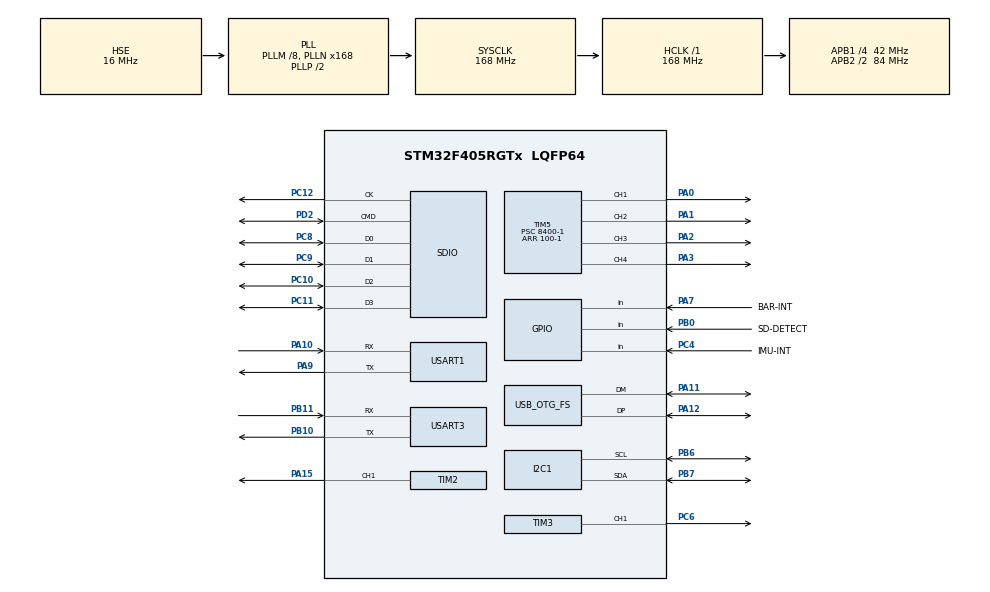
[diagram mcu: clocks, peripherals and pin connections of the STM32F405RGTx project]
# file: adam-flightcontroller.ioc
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Mcu.Family=STM32F4
Mcu.Name=STM32F405RGTx
Mcu.Package=LQFP64
NVIC.OTG_FS_IRQn=true\:0\:0\:false\:false\:true\:false\:true\:true
NVIC.PriorityGroup=NVIC_PRIORITYGROUP_4
PA0-WKUP.Signal=S_TIM5_CH1
PA1.Signal=S_TIM5_CH2
PA10.Mode=Asynchronous
PA10.Signal=USART1_RX
PA11.Mode=Device_Only
PA11.Signal=USB_OTG_FS_DM
PA12.Mode=Device_Only
PA12.Signal=USB_OTG_FS_DP
PA13.Mode=Trace_Asynchronous_SW
PA13.Signal=SYS_JTMS-SWDIO
PA14.Mode=Trace_Asynchronous_SW
PA14.Signal=SYS_JTCK-SWCLK
PA15.Signal=S_TIM2_CH1_ETR
PA2.Signal=S_TIM5_CH3
PA3.Signal=S_TIM5_CH4
PA7.GPIO_Label=BAR-INT
PA7.Signal=GPIO_Input
PA9.Mode=Asynchronous
PA9.Signal=USART1_TX
PB0.GPIO_Label=SD-DETECT
PB0.Signal=GPIO_Input
PB10.Mode=Asynchronous
PB10.Signal=USART3_TX
PB11.Mode=Asynchronous
PB11.Signal=USART3_RX
PB3.Mode=Trace_Asynchronous_SW
PB3.Signal=SYS_JTDO-SWO
PB6.Mode=I2C
PB6.Signal=I2C1_SCL
PB7.Mode=I2C
PB7.Signal=I2C1_SDA
PC10.Mode=SD_4_bits_Wide_bus
PC10.Signal=SDIO_D2
PC11.Mode=SD_4_bits_Wide_bus
PC11.Signal=SDIO_D3
PC12.Mode=SD_4_bits_Wide_bus
PC12.Signal=SDIO_CK
PC14-OSC32_IN.Mode=LSE-External-Oscillator
PC14-OSC32_IN.Signal=RCC_OSC32_IN
PC15-OSC32_OUT.Mode=LSE-External-Oscillator
PC15-OSC32_OUT.Signal=RCC_OSC32_OUT
PC4.GPIO_Label=IMU-INT
PC4.Signal=GPIO_Input
PC6.Signal=S_TIM3_CH1
PC8.Mode=SD_4_bits_Wide_bus
PC8.Signal=SDIO_D0
PC9.Mode=SD_4_bits_Wide_bus
PC9.Signal=SDIO_D1
PD2.Mode=SD_4_bits_Wide_bus
PD2.Signal=SDIO_CMD
PH0-OSC_IN.Mode=HSE-External-Oscillator
PH0-OSC_IN.Signal=RCC_OSC_IN
PH1-OSC_OUT.Mode=HSE-External-Oscillator
PH1-OSC_OUT.Signal=RCC_OSC_OUT
ProjectManager.HeapSize=0x200
ProjectManager.StackSize=0x400
ProjectManager.TargetToolchain=Makefile
RCC.48MHZClocksFreq_Value=48000000
RCC.AHBFreq_Value=168000000
RCC.APB1CLKDivider=RCC_HCLK_DIV4
RCC.APB1Freq_Value=42000000
RCC.APB1TimFreq_Value=84000000
RCC.APB2CLKDivider=RCC_HCLK_DIV2
RCC.APB2Freq_Value=84000000
RCC.APB2TimFreq_Value=168000000
RCC.CortexFreq_Value=168000000
RCC.HCLKFreq_Value=168000000
RCC.HSE_VALUE=16000000
RCC.HSI_VALUE=16000000
RCC.PLLM=8
RCC.PLLN=168
RCC.PLLQ=7
RCC.SYSCLKFreq_VALUE=168000000
RCC.SYSCLKSource=RCC_SYSCLKSOURCE_PLLCLK
RCC.VCOOutputFreq_Value=336000000
SH.S_TIM2_CH1_ETR.0=TIM2_CH1,PWM Generation1 CH1
SH.S_TIM3_CH1.0=TIM3_CH1,PWM Generation1 CH1
SH.S_TIM5_CH1.0=TIM5_CH1,PWM Generation1 CH1
SH.S_TIM5_CH2.0=TIM5_CH2,PWM Generation2 CH2
SH.S_TIM5_CH3.0=TIM5_CH3,PWM Generation3 CH3
SH.S_TIM5_CH4.0=TIM5_CH4,Output Compare4 CH4
TIM2.Channel-PWM\ Generation1\ CH1=TIM_CHANNEL_1
TIM2.Period=100-1
TIM2.Prescaler=8400-1
TIM3.Channel-PWM\ Generation1\ CH1=TIM_CHANNEL_1
TIM3.Period=100-1
TIM3.Prescaler=8400-1
TIM5.Channel-Output\ Compare4\ CH4=TIM_CHANNEL_4
TIM5.Channel-PWM\ Generation1\ CH1=TIM_CHANNEL_1
TIM5.Channel-PWM\ Generation2\ CH2=TIM_CHANNEL_2
TIM5.Channel-PWM\ Generation3\ CH3=TIM_CHANNEL_3
TIM5.Period=100-1
TIM5.Prescaler=8400-1
USART1.VirtualMode=VM_ASYNC
USART3.VirtualMode=VM_ASYNC
USB_DEVICE.CLASS_NAME_FS=CDC
USB_DEVICE.VirtualMode-CDC_FS=Cdc
USB_DEVICE.VirtualModeFS=Cdc_FS
USB_OTG_FS.VirtualMode=Device_Only
VP_TIM2_VS_ClockSourceINT.Mode=Internal
VP_TIM3_VS_ClockSourceINT.Mode=Internal
VP_TIM5_VS_ClockSourceINT.Mode=Internal
VP_USB_DEVICE_VS_USB_DEVICE_CDC_FS.Mode=CDC_FS
board=custom

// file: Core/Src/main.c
/* USER CODE BEGIN Header */
/**
  ******************************************************************************
  * @file           : main.c
  * @brief          : Main program body
  ******************************************************************************
  * @attention
  *
  * Copyright (c) 2023 STMicroelectronics.
  * All rights reserved.
  *
  * This software is licensed under terms that can be found in the LICENSE file
  * in the root directory of this software component.
  * If no LICENSE file comes with this software, it is provided AS-IS.
  *
  ******************************************************************************
  */
/* USER CODE END Header */
#include "main.h"
#include "usb_device.h"

I2C_HandleTypeDef hi2c1;

SD_HandleTypeDef hsd;

TIM_HandleTypeDef htim2;
TIM_HandleTypeDef htim3;
TIM_HandleTypeDef htim5;

UART_HandleTypeDef huart1;
UART_HandleTypeDef huart3;

void SystemClock_Config(void);
static void MX_GPIO_Init(void);
static void MX_I2C1_Init(void);
static void MX_SDIO_SD_Init(void);
static void MX_TIM2_Init(void);
static void MX_TIM3_Init(void);
static void MX_TIM5_Init(void);
static void MX_USART1_UART_Init(void);
static void MX_USART3_UART_Init(void);

int main(void)
{

  /* MCU Configuration--------------------------------------------------------*/

  /* Reset of all peripherals, Initializes the Flash interface and the Systick. */
  HAL_Init();

  /* Configure the system clock */
  SystemClock_Config();

  /* Initialize all configured peripherals */
  MX_GPIO_Init();
  MX_I2C1_Init();
  MX_SDIO_SD_Init();
  MX_TIM2_Init();
  MX_TIM3_Init();
  MX_TIM5_Init();
  MX_USART1_UART_Init();
  MX_USART3_UART_Init();
  MX_USB_DEVICE_Init();
  /* USER CODE BEGIN 2 */
  HAL_TIM_PWM_Start(&htim3, TIM_CHANNEL_1);
  uint8_t intensity = 0;

  /* USER CODE END 2 */

  /* Infinite loop */
  while (1)
  {
    htim3.Instance->CCR1 = 100 - intensity;

    intensity += 5;
    if (intensity > 100) {
      intensity = 0;
    }

    HAL_Delay(100);
  }
}

void SystemClock_Config(void)
{
  RCC_OscInitTypeDef RCC_OscInitStruct = {0};
  RCC_ClkInitTypeDef RCC_ClkInitStruct = {0};

  /** Configure the main internal regulator output voltage
  */
  __HAL_RCC_PWR_CLK_ENABLE();
  __HAL_PWR_VOLTAGESCALING_CONFIG(PWR_REGULATOR_VOLTAGE_SCALE1);

  /** Initializes the RCC Oscillators according to the specified parameters
  * in the RCC_OscInitTypeDef structure.
  */
  RCC_OscInitStruct.OscillatorType = RCC_OSCILLATORTYPE_HSE;
  RCC_OscInitStruct.HSEState = RCC_HSE_ON;
  RCC_OscInitStruct.PLL.PLLState = RCC_PLL_ON;
  RCC_OscInitStruct.PLL.PLLSource = RCC_PLLSOURCE_HSE;
  RCC_OscInitStruct.PLL.PLLM = 8;
  RCC_OscInitStruct.PLL.PLLN = 168;
  RCC_OscInitStruct.PLL.PLLP = RCC_PLLP_DIV2;
  RCC_OscInitStruct.PLL.PLLQ = 7;
  if (HAL_RCC_OscConfig(&RCC_OscInitStruct) != HAL_OK)
  {
    Error_Handler();
  }

  /** Initializes the CPU, AHB and APB buses clocks
  */
  RCC_ClkInitStruct.ClockType = RCC_CLOCKTYPE_HCLK|RCC_CLOCKTYPE_SYSCLK
                              |RCC_CLOCKTYPE_PCLK1|RCC_CLOCKTYPE_PCLK2;
  RCC_ClkInitStruct.SYSCLKSource = RCC_SYSCLKSOURCE_PLLCLK;
  RCC_ClkInitStruct.AHBCLKDivider = RCC_SYSCLK_DIV1;
  RCC_ClkInitStruct.APB1CLKDivider = RCC_HCLK_DIV4;
  RCC_ClkInitStruct.APB2CLKDivider = RCC_HCLK_DIV2;

  if (HAL_RCC_ClockConfig(&RCC_ClkInitStruct, FLASH_LATENCY_5) != HAL_OK)
  {
    Error_Handler();
  }
}

static void MX_I2C1_Init(void)
{

  hi2c1.Instance = I2C1;
  hi2c1.Init.ClockSpeed = 100000;
  hi2c1.Init.DutyCycle = I2C_DUTYCYCLE_2;
  hi2c1.Init.OwnAddress1 = 0;
  hi2c1.Init.AddressingMode = I2C_ADDRESSINGMODE_7BIT;
  hi2c1.Init.DualAddressMode = I2C_DUALADDRESS_DISABLE;
  hi2c1.Init.OwnAddress2 = 0;
  hi2c1.Init.GeneralCallMode = I2C_GENERALCALL_DISABLE;
  hi2c1.Init.NoStretchMode = I2C_NOSTRETCH_DISABLE;
  if (HAL_I2C_Init(&hi2c1) != HAL_OK)
  {
    Error_Handler();
  }

}

static void MX_SDIO_SD_Init(void)
{

  hsd.Instance = SDIO;
  hsd.Init.ClockEdge = SDIO_CLOCK_EDGE_RISING;
  hsd.Init.ClockBypass = SDIO_CLOCK_BYPASS_DISABLE;
  hsd.Init.ClockPowerSave = SDIO_CLOCK_POWER_SAVE_DISABLE;
  hsd.Init.BusWide = SDIO_BUS_WIDE_4B;
  hsd.Init.HardwareFlowControl = SDIO_HARDWARE_FLOW_CONTROL_DISABLE;
  hsd.Init.ClockDiv = 0;
  if (HAL_SD_Init(&hsd) != HAL_OK)
  {
    Error_Handler();
  }
  if (HAL_SD_ConfigWideBusOperation(&hsd, SDIO_BUS_WIDE_4B) != HAL_OK)
  {
    Error_Handler();
  }

}

static void MX_TIM2_Init(void)
{

  TIM_ClockConfigTypeDef sClockSourceConfig = {0};
  TIM_MasterConfigTypeDef sMasterConfig = {0};
  TIM_OC_InitTypeDef sConfigOC = {0};

  htim2.Instance = TIM2;
  htim2.Init.Prescaler = 8400-1;
  htim2.Init.CounterMode = TIM_COUNTERMODE_UP;
  htim2.Init.Period = 100-1;
  htim2.Init.ClockDivision = TIM_CLOCKDIVISION_DIV1;
  htim2.Init.AutoReloadPreload = TIM_AUTORELOAD_PRELOAD_DISABLE;
  if (HAL_TIM_Base_Init(&htim2) != HAL_OK)
  {
    Error_Handler();
  }
  sClockSourceConfig.ClockSource = TIM_CLOCKSOURCE_INTERNAL;
  if (HAL_TIM_ConfigClockSource(&htim2, &sClockSourceConfig) != HAL_OK)
  {
    Error_Handler();
  }
  if (HAL_TIM_PWM_Init(&htim2) != HAL_OK)
  {
    Error_Handler();
  }
  sMasterConfig.MasterOutputTrigger = TIM_TRGO_RESET;
  sMasterConfig.MasterSlaveMode = TIM_MASTERSLAVEMODE_DISABLE;
  if (HAL_TIMEx_MasterConfigSynchronization(&htim2, &sMasterConfig) != HAL_OK)
  {
    Error_Handler();
  }
  sConfigOC.OCMode = TIM_OCMODE_PWM1;
  sConfigOC.Pulse = 0;
  sConfigOC.OCPolarity = TIM_OCPOLARITY_HIGH;
  sConfigOC.OCFastMode = TIM_OCFAST_DISABLE;
  if (HAL_TIM_PWM_ConfigChannel(&htim2, &sConfigOC, TIM_CHANNEL_1) != HAL_OK)
  {
    Error_Handler();
  }
  HAL_TIM_MspPostInit(&htim2);

}

static void MX_TIM3_Init(void)
{

  TIM_ClockConfigTypeDef sClockSourceConfig = {0};
  TIM_MasterConfigTypeDef sMasterConfig = {0};
  TIM_OC_InitTypeDef sConfigOC = {0};

  htim3.Instance = TIM3;
  htim3.Init.Prescaler = 8400-1;
  htim3.Init.CounterMode = TIM_COUNTERMODE_UP;
  htim3.Init.Period = 100-1;
  htim3.Init.ClockDivision = TIM_CLOCKDIVISION_DIV1;
  htim3.Init.AutoReloadPreload = TIM_AUTORELOAD_PRELOAD_DISABLE;
  if (HAL_TIM_Base_Init(&htim3) != HAL_OK)
  {
    Error_Handler();
  }
  sClockSourceConfig.ClockSource = TIM_CLOCKSOURCE_INTERNAL;
  if (HAL_TIM_ConfigClockSource(&htim3, &sClockSourceConfig) != HAL_OK)
  {
    Error_Handler();
  }
  if (HAL_TIM_PWM_Init(&htim3) != HAL_OK)
  {
    Error_Handler();
  }
  sMasterConfig.MasterOutputTrigger = TIM_TRGO_RESET;
  sMasterConfig.MasterSlaveMode = TIM_MASTERSLAVEMODE_DISABLE;
  if (HAL_TIMEx_MasterConfigSynchronization(&htim3, &sMasterConfig) != HAL_OK)
  {
    Error_Handler();
  }
  sConfigOC.OCMode = TIM_OCMODE_PWM1;
  sConfigOC.Pulse = 0;
  sConfigOC.OCPolarity = TIM_OCPOLARITY_HIGH;
  sConfigOC.OCFastMode = TIM_OCFAST_DISABLE;
  if (HAL_TIM_PWM_ConfigChannel(&htim3, &sConfigOC, TIM_CHANNEL_1) != HAL_OK)
  {
    Error_Handler();
  }
  HAL_TIM_MspPostInit(&htim3);

}

static void MX_TIM5_Init(void)
{

  TIM_ClockConfigTypeDef sClockSourceConfig = {0};
  TIM_MasterConfigTypeDef sMasterConfig = {0};
  TIM_OC_InitTypeDef sConfigOC = {0};

  htim5.Instance = TIM5;
  htim5.Init.Prescaler = 8400-1;
  htim5.Init.CounterMode = TIM_COUNTERMODE_UP;
  htim5.Init.Period = 100-1;
  htim5.Init.ClockDivision = TIM_CLOCKDIVISION_DIV1;
  htim5.Init.AutoReloadPreload = TIM_AUTORELOAD_PRELOAD_DISABLE;
  if (HAL_TIM_Base_Init(&htim5) != HAL_OK)
  {
    Error_Handler();
  }
  sClockSourceConfig.ClockSource = TIM_CLOCKSOURCE_INTERNAL;
  if (HAL_TIM_ConfigClockSource(&htim5, &sClockSourceConfig) != HAL_OK)
  {
    Error_Handler();
  }
  if (HAL_TIM_PWM_Init(&htim5) != HAL_OK)
  {
    Error_Handler();
  }
  if (HAL_TIM_OC_Init(&htim5) != HAL_OK)
  {
    Error_Handler();
  }
  sMasterConfig.MasterOutputTrigger = TIM_TRGO_RESET;
  sMasterConfig.MasterSlaveMode = TIM_MASTERSLAVEMODE_DISABLE;
  if (HAL_TIMEx_MasterConfigSynchronization(&htim5, &sMasterConfig) != HAL_OK)
  {
    Error_Handler();
  }
  sConfigOC.OCMode = TIM_OCMODE_PWM1;
  sConfigOC.Pulse = 0;
  sConfigOC.OCPolarity = TIM_OCPOLARITY_HIGH;
  sConfigOC.OCFastMode = TIM_OCFAST_DISABLE;
  if (HAL_TIM_PWM_ConfigChannel(&htim5, &sConfigOC, TIM_CHANNEL_1) != HAL_OK)
  {
    Error_Handler();
  }
  if (HAL_TIM_PWM_ConfigChannel(&htim5, &sConfigOC, TIM_CHANNEL_2) != HAL_OK)
  {
    Error_Handler();
  }
  if (HAL_TIM_PWM_ConfigChannel(&htim5, &sConfigOC, TIM_CHANNEL_3) != HAL_OK)
  {
    Error_Handler();
  }
  sConfigOC.OCMode = TIM_OCMODE_TIMING;
  if (HAL_TIM_OC_ConfigChannel(&htim5, &sConfigOC, TIM_CHANNEL_4) != HAL_OK)
  {
    Error_Handler();
  }
  HAL_TIM_MspPostInit(&htim5);

}

static void MX_USART1_UART_Init(void)
{

  huart1.Instance = USART1;
  huart1.Init.BaudRate = 115200;
  huart1.Init.WordLength = UART_WORDLENGTH_8B;
  huart1.Init.StopBits = UART_STOPBITS_1;
  huart1.Init.Parity = UART_PARITY_NONE;
  huart1.Init.Mode = UART_MODE_TX_RX;
  huart1.Init.HwFlowCtl = UART_HWCONTROL_NONE;
  huart1.Init.OverSampling = UART_OVERSAMPLING_16;
  if (HAL_UART_Init(&huart1) != HAL_OK)
  {
    Error_Handler();
  }

}

static void MX_USART3_UART_Init(void)
{

  huart3.Instance = USART3;
  huart3.Init.BaudRate = 115200;
  huart3.Init.WordLength = UART_WORDLENGTH_8B;
  huart3.Init.StopBits = UART_STOPBITS_1;
  huart3.Init.Parity = UART_PARITY_NONE;
  huart3.Init.Mode = UART_MODE_TX_RX;
  huart3.Init.HwFlowCtl = UART_HWCONTROL_NONE;
  huart3.Init.OverSampling = UART_OVERSAMPLING_16;
  if (HAL_UART_Init(&huart3) != HAL_OK)
  {
    Error_Handler();
  }

}

static void MX_GPIO_Init(void)
{
  GPIO_InitTypeDef GPIO_InitStruct = {0};

  /* GPIO Ports Clock Enable */
  __HAL_RCC_GPIOC_CLK_ENABLE();
  __HAL_RCC_GPIOH_CLK_ENABLE();
  __HAL_RCC_GPIOA_CLK_ENABLE();
  __HAL_RCC_GPIOB_CLK_ENABLE();
  __HAL_RCC_GPIOD_CLK_ENABLE();

  /*Configure GPIO pin : BAR_INT_Pin */
  GPIO_InitStruct.Pin = BAR_INT_Pin;
  GPIO_InitStruct.Mode = GPIO_MODE_INPUT;
  GPIO_InitStruct.Pull = GPIO_NOPULL;
  HAL_GPIO_Init(BAR_INT_GPIO_Port, &GPIO_InitStruct);

  /*Configure GPIO pin : IMU_INT_Pin */
  GPIO_InitStruct.Pin = IMU_INT_Pin;
  GPIO_InitStruct.Mode = GPIO_MODE_INPUT;
  GPIO_InitStruct.Pull = GPIO_NOPULL;
  HAL_GPIO_Init(IMU_INT_GPIO_Port, &GPIO_InitStruct);

  /*Configure GPIO pin : SD_DETECT_Pin */
  GPIO_InitStruct.Pin = SD_DETECT_Pin;
  GPIO_InitStruct.Mode = GPIO_MODE_INPUT;
  GPIO_InitStruct.Pull = GPIO_NOPULL;
  HAL_GPIO_Init(SD_DETECT_GPIO_Port, &GPIO_InitStruct);

}

void Error_Handler(void)
{
  __disable_irq();
  while (1)
  {
  }
}
